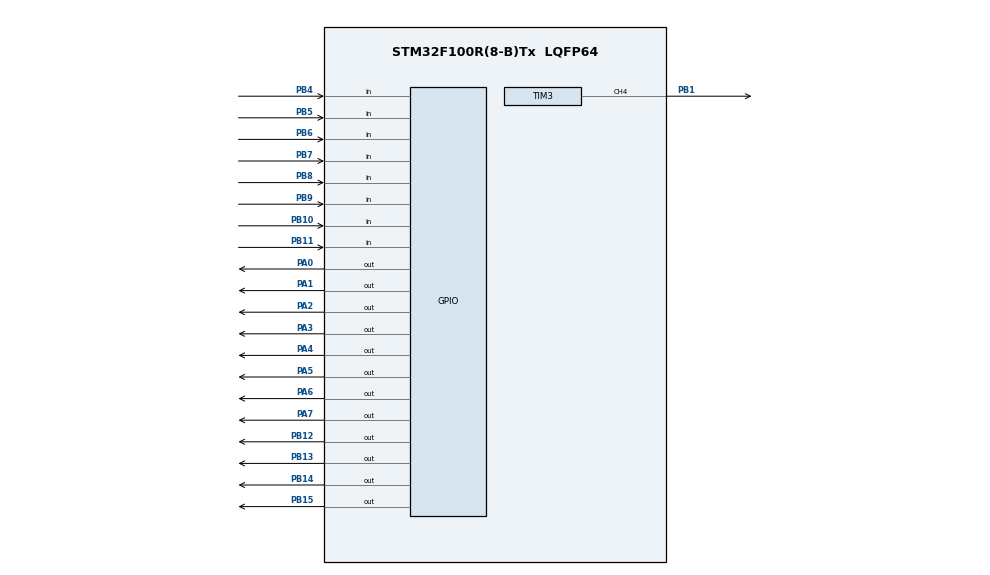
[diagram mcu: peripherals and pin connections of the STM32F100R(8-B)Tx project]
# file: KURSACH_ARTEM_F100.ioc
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Mcu.Family=STM32F1
Mcu.Name=STM32F100R(8-B)Tx
Mcu.Package=LQFP64
NVIC.PriorityGroup=NVIC_PRIORITYGROUP_4
NVIC.TIM3_IRQn=true\:0\:0\:false\:false\:true\:true\:true
NVIC.TIM6_DAC_IRQn=true\:0\:0\:false\:false\:true\:true\:true
NVIC.TIM7_IRQn=true\:0\:0\:false\:false\:true\:true\:true
PA0-WKUP.Signal=GPIO_Output
PA1.Signal=GPIO_Output
PA13.Mode=Serial_Wire
PA13.Signal=SYS_JTMS-SWDIO
PA14.Mode=Serial_Wire
PA14.Signal=SYS_JTCK-SWCLK
PA2.Signal=GPIO_Output
PA3.Signal=GPIO_Output
PA4.Signal=GPIO_Output
PA5.Signal=GPIO_Output
PA6.Signal=GPIO_Output
PA7.Signal=GPIO_Output
PB1.Signal=S_TIM3_CH4
PB10.GPIO_Mode=GPIO_MODE_INPUT
PB10.GPIO_PuPd=GPIO_PULLUP
PB10.Signal=GPIO_Input
PB11.GPIO_Mode=GPIO_MODE_INPUT
PB11.GPIO_PuPd=GPIO_PULLUP
PB11.Signal=GPIO_Input
PB12.Signal=GPIO_Output
PB13.Signal=GPIO_Output
PB14.Signal=GPIO_Output
PB15.Signal=GPIO_Output
PB4.GPIO_Mode=GPIO_MODE_INPUT
PB4.GPIO_PuPd=GPIO_PULLUP
PB4.Signal=GPIO_Input
PB5.GPIO_Mode=GPIO_MODE_INPUT
PB5.GPIO_PuPd=GPIO_PULLUP
PB5.Signal=GPIO_Input
PB6.GPIO_Mode=GPIO_MODE_INPUT
PB6.GPIO_PuPd=GPIO_PULLUP
PB6.Signal=GPIO_Input
PB7.GPIO_Mode=GPIO_MODE_INPUT
PB7.GPIO_PuPd=GPIO_PULLUP
PB7.Signal=GPIO_Input
PB8.GPIO_Mode=GPIO_MODE_INPUT
PB8.GPIO_PuPd=GPIO_PULLUP
PB8.Signal=GPIO_Input
PB9.GPIO_Mode=GPIO_MODE_INPUT
PB9.GPIO_PuPd=GPIO_PULLUP
PB9.Signal=GPIO_Input
PD0-OSC_IN.Mode=HSE-External-Oscillator
PD0-OSC_IN.Signal=RCC_OSC_IN
PD1-OSC_OUT.Mode=HSE-External-Oscillator
PD1-OSC_OUT.Signal=RCC_OSC_OUT
ProjectManager.HeapSize=0x200
ProjectManager.StackSize=0x400
ProjectManager.TargetToolchain=EWARM V8
RCC.APB1Freq_Value=8000000
RCC.APB2Freq_Value=8000000
SH.S_TIM3_CH4.0=TIM3_CH4,PWM Generation4 CH4
TIM3.Channel-PWM\ Generation4\ CH4=TIM_CHANNEL_4
TIM3.Period=3200
TIM6.Period=200
TIM6.Prescaler=200
TIM7.Period=1000
TIM7.Prescaler=7999
VP_TIM3_VS_ClockSourceINT.Mode=Internal
VP_TIM6_VS_ClockSourceINT.Mode=Enable_Timer
VP_TIM7_VS_ClockSourceINT.Mode=Enable_Timer
board=custom

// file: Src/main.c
/* USER CODE BEGIN Header */
/**
  ******************************************************************************
  * @file           : main.c
  * @brief          : Main program body
  ******************************************************************************
  * @attention
  *
  * <h2><center>&copy; Copyright (c) 2019 STMicroelectronics.
  * All rights reserved.</center></h2>
  *
  * This software component is licensed by ST under BSD 3-Clause license,
  * the "License"; You may not use this file except in compliance with the
  * License. You may obtain a copy of the License at:
  *                        opensource.org/licenses/BSD-3-Clause
  *
  ******************************************************************************
  */
/* USER CODE END Header */

#include "main.h"

/* USER CODE BEGIN Includes */
#include "global.h"
/* USER CODE END Includes */

void SystemClock_Config(void);
static void MX_GPIO_Init(void);
static void MX_TIM3_Init(void);
static void MX_TIM6_Init(void);
static void MX_TIM7_Init(void);

int main(void)
{

  /* MCU Configuration--------------------------------------------------------*/

  /* Reset of all peripherals, Initializes the Flash interface and the Systick. */
  HAL_Init();

  /* Configure the system clock */
  SystemClock_Config();

  /* Initialize all configured peripherals */
  MX_GPIO_Init();
  MX_TIM3_Init();
  MX_TIM6_Init();
  MX_TIM7_Init();
  /* USER CODE BEGIN 2 */
  LL_TIM_EnableIT_UPDATE(TIM6);
  LL_TIM_EnableCounter(TIM6);
  LL_TIM_EnableIT_UPDATE(TIM7);
  LL_TIM_EnableCounter(TIM7);
  LL_TIM_CC_EnableChannel(TIM3,LL_TIM_CHANNEL_CH4);

  LL_TIM_EnableIT_UPDATE(TIM3);
  LL_TIM_EnableCounter(TIM3);
  /* USER CODE END 2 */

  /* Infinite loop */
  while (1)
  {

    /* USER CODE BEGIN 3 */
    //LL_TIM_OC_SetCompareCH4(TIM3, FREQ);
  }
  /* USER CODE END 3 */
}

void SystemClock_Config(void)
{
  LL_RCC_HSI_SetCalibTrimming(16);
  LL_RCC_HSI_Enable();

   /* Wait till HSI is ready */
  while(LL_RCC_HSI_IsReady() != 1)
  {

  }
  LL_RCC_SetAHBPrescaler(LL_RCC_SYSCLK_DIV_1);
  LL_RCC_SetAPB1Prescaler(LL_RCC_APB1_DIV_1);
  LL_RCC_SetAPB2Prescaler(LL_RCC_APB2_DIV_1);
  LL_RCC_SetSysClkSource(LL_RCC_SYS_CLKSOURCE_HSI);

   /* Wait till System clock is ready */
  while(LL_RCC_GetSysClkSource() != LL_RCC_SYS_CLKSOURCE_STATUS_HSI)
  {

  }
  LL_Init1msTick(8000000);
  LL_SYSTICK_SetClkSource(LL_SYSTICK_CLKSOURCE_HCLK);
  LL_SetSystemCoreClock(8000000);
}

static void MX_TIM3_Init(void)
{

  LL_TIM_InitTypeDef TIM_InitStruct = {0};
  LL_TIM_OC_InitTypeDef TIM_OC_InitStruct = {0};

  LL_GPIO_InitTypeDef GPIO_InitStruct = {0};

  /* Peripheral clock enable */
  LL_APB1_GRP1_EnableClock(LL_APB1_GRP1_PERIPH_TIM3);

  /* TIM3 interrupt Init */
  NVIC_SetPriority(TIM3_IRQn, NVIC_EncodePriority(NVIC_GetPriorityGrouping(),0, 0));
  NVIC_EnableIRQ(TIM3_IRQn);

  TIM_InitStruct.Prescaler = 0;
  TIM_InitStruct.CounterMode = LL_TIM_COUNTERMODE_UP;
  TIM_InitStruct.Autoreload = 3200;
  TIM_InitStruct.ClockDivision = LL_TIM_CLOCKDIVISION_DIV1;
  LL_TIM_Init(TIM3, &TIM_InitStruct);
  LL_TIM_DisableARRPreload(TIM3);
  LL_TIM_SetClockSource(TIM3, LL_TIM_CLOCKSOURCE_INTERNAL);
  LL_TIM_OC_EnablePreload(TIM3, LL_TIM_CHANNEL_CH4);
  TIM_OC_InitStruct.OCMode = LL_TIM_OCMODE_PWM1;
  TIM_OC_InitStruct.OCState = LL_TIM_OCSTATE_DISABLE;
  TIM_OC_InitStruct.OCNState = LL_TIM_OCSTATE_DISABLE;
  TIM_OC_InitStruct.CompareValue = 0;
  TIM_OC_InitStruct.OCPolarity = LL_TIM_OCPOLARITY_HIGH;
  LL_TIM_OC_Init(TIM3, LL_TIM_CHANNEL_CH4, &TIM_OC_InitStruct);
  LL_TIM_OC_DisableFast(TIM3, LL_TIM_CHANNEL_CH4);
  LL_TIM_SetTriggerOutput(TIM3, LL_TIM_TRGO_RESET);
  LL_TIM_DisableMasterSlaveMode(TIM3);
  LL_APB2_GRP1_EnableClock(LL_APB2_GRP1_PERIPH_GPIOB);
  /**TIM3 GPIO Configuration
  PB1   ------> TIM3_CH4
  */
  GPIO_InitStruct.Pin = LL_GPIO_PIN_1;
  GPIO_InitStruct.Mode = LL_GPIO_MODE_ALTERNATE;
  GPIO_InitStruct.Speed = LL_GPIO_SPEED_FREQ_LOW;
  GPIO_InitStruct.OutputType = LL_GPIO_OUTPUT_PUSHPULL;
  LL_GPIO_Init(GPIOB, &GPIO_InitStruct);

}

static void MX_TIM6_Init(void)
{

  LL_TIM_InitTypeDef TIM_InitStruct = {0};

  /* Peripheral clock enable */
  LL_APB1_GRP1_EnableClock(LL_APB1_GRP1_PERIPH_TIM6);

  /* TIM6 interrupt Init */
  NVIC_SetPriority(TIM6_DAC_IRQn, NVIC_EncodePriority(NVIC_GetPriorityGrouping(),0, 0));
  NVIC_EnableIRQ(TIM6_DAC_IRQn);

  TIM_InitStruct.Prescaler = 200;
  TIM_InitStruct.CounterMode = LL_TIM_COUNTERMODE_UP;
  TIM_InitStruct.Autoreload = 200;
  LL_TIM_Init(TIM6, &TIM_InitStruct);
  LL_TIM_DisableARRPreload(TIM6);
  LL_TIM_SetTriggerOutput(TIM6, LL_TIM_TRGO_RESET);
  LL_TIM_DisableMasterSlaveMode(TIM6);

}

static void MX_TIM7_Init(void)
{

  LL_TIM_InitTypeDef TIM_InitStruct = {0};

  /* Peripheral clock enable */
  LL_APB1_GRP1_EnableClock(LL_APB1_GRP1_PERIPH_TIM7);

  /* TIM7 interrupt Init */
  NVIC_SetPriority(TIM7_IRQn, NVIC_EncodePriority(NVIC_GetPriorityGrouping(),0, 0));
  NVIC_EnableIRQ(TIM7_IRQn);

  TIM_InitStruct.Prescaler = 7999;
  TIM_InitStruct.CounterMode = LL_TIM_COUNTERMODE_UP;
  TIM_InitStruct.Autoreload = 1000;
  LL_TIM_Init(TIM7, &TIM_InitStruct);
  LL_TIM_DisableARRPreload(TIM7);
  LL_TIM_SetTriggerOutput(TIM7, LL_TIM_TRGO_RESET);
  LL_TIM_DisableMasterSlaveMode(TIM7);

}

static void MX_GPIO_Init(void)
{
  GPIO_InitTypeDef GPIO_InitStruct = {0};

  /* GPIO Ports Clock Enable */
  __HAL_RCC_GPIOD_CLK_ENABLE();
  __HAL_RCC_GPIOA_CLK_ENABLE();
  __HAL_RCC_GPIOB_CLK_ENABLE();

  /*Configure GPIO pin Output Level */
  HAL_GPIO_WritePin(GPIOA, GPIO_PIN_0|GPIO_PIN_1|GPIO_PIN_2|GPIO_PIN_3
                          |GPIO_PIN_4|GPIO_PIN_5|GPIO_PIN_6|GPIO_PIN_7, GPIO_PIN_RESET);

  /*Configure GPIO pin Output Level */
  HAL_GPIO_WritePin(GPIOB, GPIO_PIN_12|GPIO_PIN_13|GPIO_PIN_14|GPIO_PIN_15, GPIO_PIN_RESET);

  /*Configure GPIO pins : PA0 PA1 PA2 PA3
                           PA4 PA5 PA6 PA7 */
  GPIO_InitStruct.Pin = GPIO_PIN_0|GPIO_PIN_1|GPIO_PIN_2|GPIO_PIN_3
                          |GPIO_PIN_4|GPIO_PIN_5|GPIO_PIN_6|GPIO_PIN_7;
  GPIO_InitStruct.Mode = GPIO_MODE_OUTPUT_PP;
  GPIO_InitStruct.Pull = GPIO_NOPULL;
  GPIO_InitStruct.Speed = GPIO_SPEED_FREQ_LOW;
  HAL_GPIO_Init(GPIOA, &GPIO_InitStruct);

  /*Configure GPIO pins : PB10 PB11 PB4 PB5
                           PB6 PB7 PB8 PB9 */
  GPIO_InitStruct.Pin = GPIO_PIN_10|GPIO_PIN_11|GPIO_PIN_4|GPIO_PIN_5
                          |GPIO_PIN_6|GPIO_PIN_7|GPIO_PIN_8|GPIO_PIN_9;
  GPIO_InitStruct.Mode = GPIO_MODE_INPUT;
  GPIO_InitStruct.Pull = GPIO_PULLUP;
  HAL_GPIO_Init(GPIOB, &GPIO_InitStruct);

  /*Configure GPIO pins : PB12 PB13 PB14 PB15 */
  GPIO_InitStruct.Pin = GPIO_PIN_12|GPIO_PIN_13|GPIO_PIN_14|GPIO_PIN_15;
  GPIO_InitStruct.Mode = GPIO_MODE_OUTPUT_PP;
  GPIO_InitStruct.Pull = GPIO_NOPULL;
  GPIO_InitStruct.Speed = GPIO_SPEED_FREQ_LOW;
  HAL_GPIO_Init(GPIOB, &GPIO_InitStruct);

}

void Error_Handler(void)
{
}

/************************ (C) COPYRIGHT STMicroelectronics *****END OF FILE****/
